# Auxilary_Supply_1 register map
Vendor: Texas Instruments
Peripheral module from a debugger description file (folder msp430).
Registers are 16-bit, read-write, reset 0x0 unless marked. A register's access mark holds for its fields unless they carry their own. Offsets are as the file gives them; lines under a group give offsets from that group; [hi:lo] are bit positions; {n}, {i} and the like mark numbered series; 'fields as' and 'values as' point back to an identical list; <NAME> marks a mode.

## Auxilary_Supply
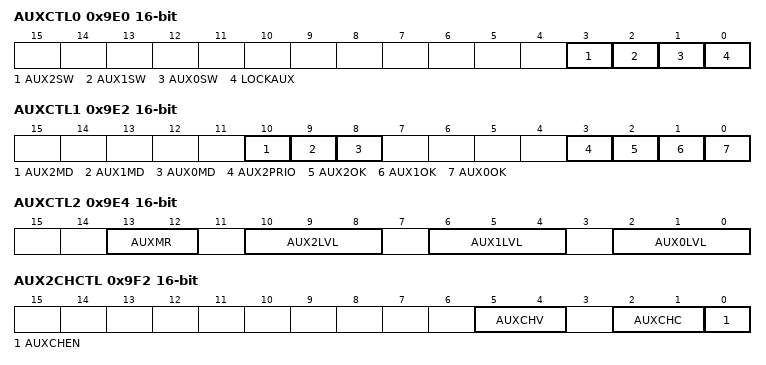
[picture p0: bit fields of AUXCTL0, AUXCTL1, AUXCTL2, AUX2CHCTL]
0x9E0 AUXCTL0 — Auxiliary Supply Control register 0
  [3] AUX2SW — AUX2 switch state.
  [2] AUX1SW — AUX1 switch state.
  [1] AUX0SW — DVCC switch state.
  [0] LOCKAUX — Lock auxiliary supply system.
0x9E2 AUXCTL1 — Auxiliary Supply Control register 1
  [10] AUX2MD — AUX2 supply mode.
  [9] AUX1MD — AUX1 supply mode.
  [8] AUX0MD — DVCC supply mode.
  [3] AUX2PRIO — Auxiliary supply AUX2 priority.
  [2] AUX2OK — AUX 2 supply okay flag.
  [1] AUX1OK — AUX 1 supply okay flag.
  [0] AUX0OK — DVCC okay flag.
0x9E4 AUXCTL2 — Auxiliary Supply Control register 2
  [13:12] AUXMR — Auxiliary supply monitoring rate Bit: 0
    {v}=Auxiliary supply monitoring rate: {v} (v=0..3)
  [10:8] AUX2LVL — AUX2 supply threshold level Bit: 0
    {v}=AUX2 supply threshold level: {v} (v=0..7)
  [6:4] AUX1LVL — AUX1 supply threshold level Bit: 0
    {v}=AUX1 supply threshold level: {v} (v=0..7)
  [2:0] AUX0LVL — DVCC supply threshold level Bit: 0
    {v}=DVCC supply threshold level: {v} (v=0..7)
0x9F2 AUX2CHCTL — AUX2 Charger Control register
  [5:4] AUXCHV — Charger end voltage Bit: 0
    {v}=Charger end voltage: {v} (v=0..3)
  [2:1] AUXCHC — Charger charge current Bit: 0
    {v}=Charger charge current: {v} (v=0..3)
  [0] AUXCHEN — Lock auxiliary supply system.
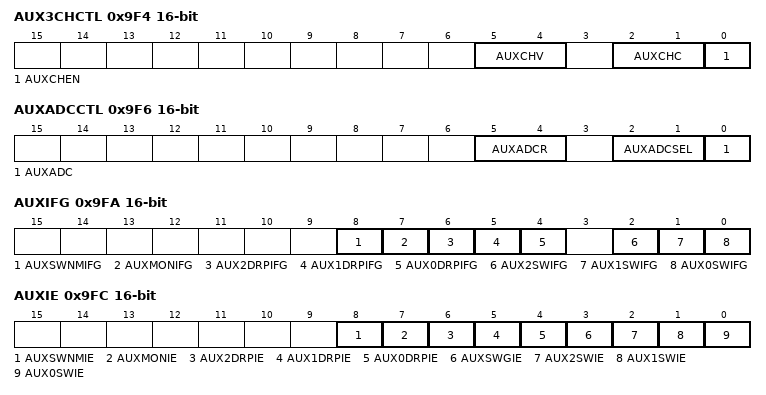
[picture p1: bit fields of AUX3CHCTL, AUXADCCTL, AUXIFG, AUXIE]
0x9F4 AUX3CHCTL — AUX3 Charger Control register
  fields as AUX2CHCTL
0x9F6 AUXADCCTL — AUX ADC Control
  [5:4] AUXADCR — Load resistance Bit: 0
    {v}=Load resistance: {v} (v=0..3)
  [2:1] AUXADCSEL — Select supply to be measured with ADC Bit: 0
    0=Select supply to be measured with ADC: DVCC; 1=Select supply to be measured with ADC: AUXVCC1; 2=Select supply to be measured with ADC: AUXVCC2; 3=Select supply to be measured with ADC: AUXVCC3
  [0] AUXADC — Auxiliary supplies to ADC
0x9FA AUXIFG — AUX Interrupt Flag
  [8] AUXSWNMIFG — Supplies switched (non-)maskable interrupt flag
  [7] AUXMONIFG — Supply monitor interrupt flag
  [6] AUX2DRPIFG — AUX2 dropped below its threshold interrupt flag
  [5] AUX1DRPIFG — AUX1 dropped below its threshold interrupt flag
  [4] AUX0DRPIFG — DVCC dropped below its threshold interrupt flag
  [2] AUX2SWIFG — Switched to AUX2 interrupt flag
  [1] AUX1SWIFG — Switched to AUX1 interrupt flag
  [0] AUX0SWIFG — Switched to DVCC interrupt flag
0x9FC AUXIE — AUX Interrupt Enable
  [8] AUXSWNMIE — Supplies switched (non-)maskable interrupt enable
  [7] AUXMONIE — Supply monitor interrupt enable
  [6] AUX2DRPIE — AUX2 dropped below its threshold interrupt enable
  [5] AUX1DRPIE — AUX1 dropped below its threshold interrupt enable
  [4] AUX0DRPIE — DVCC dropped below its threshold interrupt enable
  [3] AUXSWGIE — Global supply switched interrupt enable.
  [2] AUX2SWIE — Switched to AUX2 interrupt enable
  [1] AUX1SWIE — Switched to AUX1 interrupt enable
  [0] AUX0SWIE — Switched to DVCC interrupt enable
0x9FE AUXIV access not given reset not defined — AUX Interrupt Vector Word
